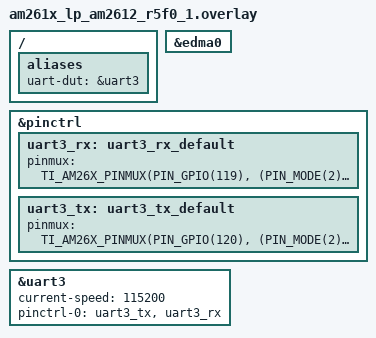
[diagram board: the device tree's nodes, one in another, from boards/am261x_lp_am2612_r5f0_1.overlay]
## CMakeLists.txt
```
# SPDX-License-Identifier: Apache-2.0

cmake_minimum_required(VERSION 3.20.0)

find_package(Zephyr REQUIRED HINTS $ENV{ZEPHYR_BASE})
project(uart_dma_loopback_test)

target_sources(app PRIVATE src/main.c)
```

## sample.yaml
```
sample:
  name: AM261x UART DMA Loopback Test
  description: >
    Demonstrates UART with DMA loopback operations on TI AM261x LaunchPad.
    Transmits data via UART with DMA, enables loopback mode to receive the same data,
    and verifies data integrity.
    NOTE: This test uses cache APIs

common:
  tags:
    - sample
    - dma
    - uart
  integration_platforms:
    - am261x_lp/am2612/r5f0_0
  harness: console
  harness_config:
    type: one_line
    regex:
      - "UART DMA loopback test passed!"

tests:
  sample.boards.ti.am261x_lp.uart_dma_loopback_test.normal:
    tags: tests
    filter: CONFIG_CACHE_MANAGEMENT and CONFIG_UART_ASYNC_API and dt_alias_exists("uart-dut")
```

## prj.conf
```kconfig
CONFIG_PRINTK=y

CONFIG_DMA=y
CONFIG_UART_ASYNC_API=y
```

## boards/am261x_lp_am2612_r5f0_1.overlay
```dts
/*
 * Copyright (c) 2025 Texas Instruments Incorporated
 *
 * SPDX-License-Identifier: Apache-2.0
 */

/*
 * Hardware Setup: Connect UART TX and RX pins with a jumper wire.
 * See pinctrl configuration below for pin assignments.
 */

#include <zephyr/dt-bindings/pinctrl/ti-am26x-pinctrl.h>

/ {
	aliases {
		uart-dut = &uart3;
	};
};

&edma0 {
	status = "okay";
};

&pinctrl {
	uart3_rx: uart3_rx_default {
		pinmux = <TI_AM26X_PINMUX(PIN_GPIO(119),
			(PIN_MODE(2) | PIN_PULL_DISABLE | PIN_SLEW_RATE_LOW))>;
	};

	uart3_tx: uart3_tx_default {
		pinmux = <TI_AM26X_PINMUX(PIN_GPIO(120),
			(PIN_MODE(2) | PIN_PULL_DISABLE | PIN_SLEW_RATE_LOW))>;
	};
};

&uart3 {
	status = "okay";
	current-speed = <115200>;
	pinctrl-0 = <&uart3_tx &uart3_rx>;
	pinctrl-names = "default";
};
```

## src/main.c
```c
/*
 * Copyright (c) 2025 Texas Instruments Incorporated
 *
 * SPDX-License-Identifier: Apache-2.0
 */

#include <zephyr/kernel.h>
#include <zephyr/device.h>
#include <zephyr/drivers/dma.h>
#include <zephyr/drivers/uart.h>
#include <zephyr/sys/printk.h>
#include <string.h>

#include <zephyr/cache.h>

/*
 * Hardware Setup Required:
 * Connect UART TX to UART RX with a jumper wire for hardware loopback.
 * Refer to your board's overlay file for specific pin assignments.
 */

/*
 * Get UART device from the devicetree uart_dut alias. This is mandatory.
 */
#define UART_DUT_NODE DT_ALIAS(uart_dut)
#if !DT_NODE_HAS_STATUS_OKAY(UART_DUT_NODE)
#error "Unsupported board: uart_dut devicetree alias is not defined"
#endif

int main(void)
{
	const struct device *uart_dev = DEVICE_DT_GET(UART_DUT_NODE);
	char rx_buf[96] __aligned(CONFIG_DCACHE_LINE_SIZE);
	char tx_buf[96] __aligned(CONFIG_DCACHE_LINE_SIZE) =
		"Hi from UART. This is an intentionally long message, my friend! Lorem Ipsum!";
	int err;

	sys_cache_data_flush_range((void *)tx_buf, sizeof(tx_buf));
	uart_rx_enable(uart_dev, rx_buf, sizeof(rx_buf), SYS_FOREVER_US);

	err = uart_tx(uart_dev, tx_buf, sizeof(tx_buf), SYS_FOREVER_US);
	if (err) {
		printk("Unexpected error encountered with error code %d\n", err);
		return err;
	}

	k_sleep(K_MSEC(100));

	uart_rx_disable(uart_dev);

	sys_cache_data_invd_range((void *)rx_buf, sizeof(rx_buf));
	printk("%s\n", rx_buf);

	if (memcmp(tx_buf, rx_buf, sizeof(tx_buf))) {
		printk("UART DMA loopback test failed!\n");
		return -1;
	}

	printk("UART DMA loopback test passed!\n");
	return 0;
}
```
